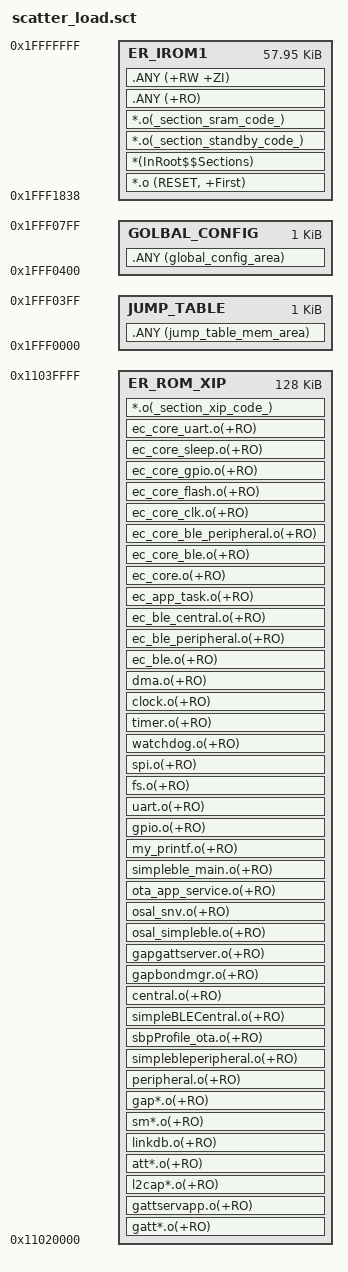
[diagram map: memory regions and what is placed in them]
; *************************************************************
; *** Scatter-Loading Description File generated by uVision ***
; *************************************************************

LR_IROM1 0x1fff1838 0x0E7C8 {  ; load region size_region
 ER_IROM1 0x1fff1838 0x0E7C8  {  ; load address = execution address
  *.o (RESET, +First)
  *(InRoot$$Sections)
  *.o(_section_standby_code_)
  *.o(_section_sram_code_)
  .ANY (+RO)
  .ANY (+RW +ZI)
 }
 ; ER_IROM2 0x1fffc000 0x04000  {  ; load address = execution address
 ; rf_phy_driver.o(i.rf_phy_dtm*)
  ;rf_phy_driver.o(i.rf_phy_direct_*)
 ;}
}
LR_ROM_JT_GC  0x1fff0000 0x00800 {
  JUMP_TABLE 0x1fff0000 0x00400  {
   .ANY (jump_table_mem_area)

  }
  GOLBAL_CONFIG 0x1fff0400 0x00400  {
   .ANY (global_config_area)

  }
 }
LR_ROM_XIP  0x11020000 0x020000 {
  ER_ROM_XIP 0x11020000 0x020000  {  ; load address = execution address

	gatt*.o(+RO)
	gattservapp.o(+RO)
	l2cap*.o(+RO)
	att*.o(+RO)
	linkdb.o(+RO)
	sm*.o(+RO)
	gap*.o(+RO)
	peripheral.o(+RO)
	simplebleperipheral.o(+RO)
	sbpProfile_ota.o(+RO)

	simpleBLECentral.o(+RO)
	central.o(+RO)
	gapbondmgr.o(+RO)
	gapgattserver.o(+RO)
	osal_simpleble.o(+RO)
	osal_snv.o(+RO)
	ota_app_service.o(+RO)
	simpleble_main.o(+RO)

	;pwrmgr.o(+RO);!!!!!!!!
	;flash.o(+RO)!!!!!!!!
	my_printf.o(+RO)
	gpio.o(+RO)
	uart.o(+RO)
	fs.o(+RO)
	;osal_snv.o(+RO)
	;adc.o(+RO)
	spi.o(+RO)
	watchdog.o(+RO)
	timer.o(+RO)
	clock.o(+RO)
	dma.o(+RO)
	;pwm.o(+RO)
	;spiflash.o(+RO)

	ec_ble.o(+RO)
	ec_ble_peripheral.o(+RO)
	ec_ble_central.o(+RO)
	ec_app_task.o(+RO)

	ec_core.o(+RO)
	;ec_core_adc.o(+RO)
	ec_core_ble.o(+RO)
	;ec_core_ble_central.o(+RO)
	ec_core_ble_peripheral.o(+RO)
	ec_core_clk.o(+RO)
	;ec_core_delay.o(+RO)
	ec_core_flash.o(+RO)
	ec_core_gpio.o(+RO)
	;ec_core_i2c.o(+RO)
	;ec_core_key.o(+RO)
	;ec_core_led.o(+RO)
	;ec_core_printf.o(+RO)
	;ec_core_pwm.o(+RO)
	ec_core_sleep.o(+RO)
	;ec_core_timer.o(+RO)
	ec_core_uart.o(+RO)
	;ec_core_wdg.o(+RO)


	;ec_app_flash.o(+RO)
	;RsBle.o(+RO)
	;RsBlePeripheral.o(+RO)

	;ec_app_sct_test.o(+RO)

	*.o(_section_xip_code_)
 }
}



